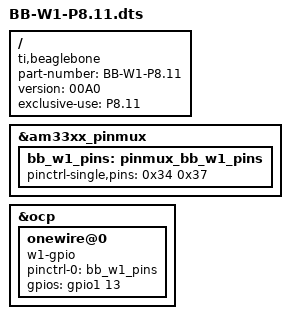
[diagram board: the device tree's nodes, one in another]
/*
 * Copyright (C) 2012 Texas Instruments Incorporated - http://www.ti.com/
 *
 * This program is free software; you can redistribute it and/or modify
 * it under the terms of the GNU General Public License version 2 as
 * published by the Free Software Foundation.
 *
 * Modified  by Russell Senior from the weather cape's DTS file.
 * Minor formatting by C W Rose.
 *
 * All this from here:
 * http://www.bonebrews.com/
 *          temperature-monitoring-with-the-ds18b20-on-a-beaglebone-black/
 *
 * 2016-12-19 Louis Marais
 * Modified the 'gpios = <...' line: changed gpio2 to gpio1 (the '2' was
 * a quirk in the older kernels).
 *
 * 2016-12-20 Louis Marais
 * I want to install this on the BBB OpenTTP system on plywood, so I had to undo
 * the change above. I added a comment to make it obvious what needs to happen.
 *
 */
/dts-v1/;
/plugin/;

/ {
    compatible = "ti,beaglebone", "ti,beaglebone-black";
    part-number = "BB-W1-P8.11";
    version = "00A0";

    exclusive-use = "P8.11";

    fragment@0 {
        target = <&am33xx_pinmux>;
        __overlay__ {
             bb_w1_pins: pinmux_bb_w1_pins {
                 pinctrl-single,pins =  <0x34 0x37 /* gpmc_ad13.gpio1_13, OMAP_PIN_INPUT_PULLUP | OMAP_MUX_MODE7 - w1-gpio */ >;
             };
        };
    };

    fragment@1 {
        target = <&ocp>;
        __overlay__ {
            onewire@0 {
                status          = "okay";
                compatible      = "w1-gpio";
                pinctrl-names   = "default";
                pinctrl-0       = <&bb_w1_pins>;
                gpios = <&gpio1 13 0>; /* gpio1 for 0 based counting, gpio2 for 1 based counting */
            };
        };
    };
};

